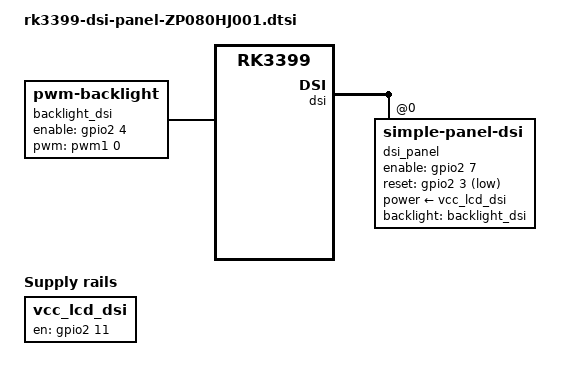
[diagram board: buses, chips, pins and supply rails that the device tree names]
/*
 * Copyright (c) 2016 Fuzhou Rockchip Electronics Co., Ltd
 *
 * This file is dual-licensed: you can use it either under the terms
 * of the GPL or the X11 license, at your option. Note that this dual
 * licensing only applies to this file, and not this project as a
 * whole.
 *
 *  a) This file is free software; you can redistribute it and/or
 *     modify it under the terms of the GNU General Public License as
 *     published by the Free Software Foundation; either version 2 of the
 *     License, or (at your option) any later version.
 *
 *     This file is distributed in the hope that it will be useful,
 *     but WITHOUT ANY WARRANTY; without even the implied warranty of
 *     MERCHANTABILITY or FITNESS FOR A PARTICULAR PURPOSE.  See the
 *     GNU General Public License for more details.
 *
 * Or, alternatively,
 *
 *  b) Permission is hereby granted, free of charge, to any person
 *     obtaining a copy of this software and associated documentation
 *     files (the "Software"), to deal in the Software without
 *     restriction, including without limitation the rights to use,
 *     copy, modify, merge, publish, distribute, sublicense, and/or
 *     sell copies of the Software, and to permit persons to whom the
 *     Software is furnished to do so, subject to the following
 *     conditions:
 *
 *     The above copyright notice and this permission notice shall be
 *     included in all copies or substantial portions of the Software.
 *
 *     THE SOFTWARE IS PROVIDED "AS IS", WITHOUT WARRANTY OF ANY KIND,
 *     EXPRESS OR IMPLIED, INCLUDING BUT NOT LIMITED TO THE WARRANTIES
 *     OF MERCHANTABILITY, FITNESS FOR A PARTICULAR PURPOSE AND
 *     NONINFRINGEMENT. IN NO EVENT SHALL THE AUTHORS OR COPYRIGHT
 *     HOLDERS BE LIABLE FOR ANY CLAIM, DAMAGES OR OTHER LIABILITY,
 *     WHETHER IN AN ACTION OF CONTRACT, TORT OR OTHERWISE, ARISING
 *     FROM, OUT OF OR IN CONNECTION WITH THE SOFTWARE OR THE USE OR
 *     OTHER DEALINGS IN THE SOFTWARE.
 */

/ {
	vcc_lcd_dsi: vcc-lcd-dsi-regulator {
		compatible = "regulator-fixed";
		status = "okay";
		regulator-always-on;
		regulator-boot-on;
		enable-active-high;
		gpio = <&gpio2 11 GPIO_ACTIVE_HIGH>;
		regulator-name = "vcc_lcd_dsi";
	};

	backlight_dsi: backlight-dsi {
		status = "okay";
		compatible = "pwm-backlight";
		pwms = <&pwm1 0 25000 0>;
		brightness-levels = <
			  0   0   1   1   2   2   3   3
			  4   4   5   5   6   6   7   7
			  8   8   9   9  10  10  11  11
			 12  12  13  13  14  14  15  15
			 16  16  17  17  18  18  19  19
			 20  20  21  21  22  22  23  23
			 24  24  25  25  26  26  27  27
			 28  28  29  29  30  30  31  31
			 32  32  33  33  34  34  35  35
			 36  36  37  37  38  38  39  39
			 40  40  41  41  42  42  43  43
			 44  44  45  45  46  46  47  47
			 48  48  49  49  50  50  51  51
			 52  52  53  53  54  54  55  55
			 56  56  57  57  58  58  59  59
			 60  60  61  61  62  62  63  63
			 64  64  65  65  66  66  67  67
			 68  68  69  69  70  70  71  71
			 72  72  73  73  74  74  75  75
			 76  76  77  77  78  78  79  79
			 80  80  81  81  81  82  83  83
			 84  84  85  85  86  86  87  87
			 88  88  89  89  90  90  91  91
			 92  92  93  93  94  94  95  95
			 96  96  97  97  98  98  99  99
			 100 100 101 101 102 102 103 103
			 104 104 105 105 106 106 107 107
			 108 108 109 109 110 110 110 110
			 111 111 112 112 113 113 114 114
			 115 115 116 116 117 117 118 118
			 119 119 120 120 121 121 122 122
			 123 123 124 124 125 125 126>;
		default-brightness-level = <60>;
		enable-gpios = <&gpio2 4 GPIO_ACTIVE_HIGH>;
	};
};

&dsi {
	status = "okay";
//	rockchip,lane-rate = <1000>;

	dsi_panel: panel@0 {
		compatible ="simple-panel-dsi";
		status = "okay";
		reg = <0>;
		reset-delay-ms = <1>;
		init-delay-ms = <20>;
		enable-delay-ms = <120>;
		prepare-delay-ms = <2>;
		disable-delay-ms = <50>;
		unprepare-delay-ms = <20>;
		backlight = <&backlight_dsi>;
		power-supply = <&vcc_lcd_dsi>;
		enable-gpios = <&gpio2 7 GPIO_ACTIVE_HIGH>;
		reset-gpios = <&gpio2 3 GPIO_ACTIVE_LOW>;
		dsi,format = <MIPI_DSI_FMT_RGB888>;
		dsi,flags = <(MIPI_DSI_MODE_VIDEO | MIPI_DSI_MODE_VIDEO_BURST)>;
		dsi,lanes = <4>;

#if 0
		panel-init-sequence = [
			 15 00 02 E0 00
			 15 00 02 E1 93
			 15 00 02 E2 65
			 15 00 02 E3 F8
			 15 00 02 80 03
			 15 00 02 E0 01
			 15 00 02 00 00
			 15 00 02 01 6F
			 15 00 02 03 00
			 15 00 02 04 6A
			 15 00 02 17 00
			 15 00 02 18 AF
			 15 00 02 19 01
			 15 00 02 1A 00
			 15 00 02 1B AF
			 15 00 02 1C 01
			 15 00 02 1F 3E
			 15 00 02 20 28
			 15 00 02 21 28
			 15 00 02 22 7E
			 15 00 02 35 26
			 15 00 02 37 09
			 15 00 02 38 04
			 15 00 02 39 00
			 15 00 02 3A 01
			 15 00 02 3C 7C
			 15 00 02 3D FF
			 15 00 02 3E FF
			 15 00 02 3F 7F
			 15 00 02 40 06
			 15 00 02 41 A0
			 15 00 02 42 81
			 15 00 02 43 08
			 15 00 02 44 0B
			 15 00 02 45 28
			 15 00 02 55 01
			 15 00 02 57 69
			 15 00 02 59 0A
			 15 00 02 5A 28
			 15 00 02 5B 14
			 15 00 02 5D 7C
			 15 00 02 5E 65
			 15 00 02 5F 55
			 15 00 02 60 47
			 15 00 02 61 43
			 15 00 02 62 32
			 15 00 02 63 34
			 15 00 02 64 1C
			 15 00 02 65 33
			 15 00 02 66 31
			 15 00 02 67 30
			 15 00 02 68 4E
			 15 00 02 69 3C
			 15 00 02 6A 44
			 15 00 02 6B 35
			 15 00 02 6C 31
			 15 00 02 6D 23
			 15 00 02 6E 11
			 15 00 02 6F 00
			 15 00 02 70 7C
			 15 00 02 71 65
			 15 00 02 72 55
			 15 00 02 73 47
			 15 00 02 74 43
			 15 00 02 75 32
			 15 00 02 76 34
			 15 00 02 77 1C
			 15 00 02 78 33
			 15 00 02 79 31
			 15 00 02 7A 30
			 15 00 02 7B 4E
			 15 00 02 7C 3C
			 15 00 02 7D 44
			 15 00 02 7E 35
			 15 00 02 7F 31
			 15 00 02 80 23
			 15 00 02 81 11
			 15 00 02 82 00
			 15 00 02 E0 02
			 15 00 02 00 1E
			 15 00 02 01 1E
			 15 00 02 02 41
			 15 00 02 03 41
			 15 00 02 04 1F
			 15 00 02 05 1F
			 15 00 02 06 1F
			 15 00 02 07 1F
			 15 00 02 08 1F
			 15 00 02 09 1F
			 15 00 02 0A 1E
			 15 00 02 0B 1E
			 15 00 02 0C 1F
			 15 00 02 0D 47
			 15 00 02 0E 47
			 15 00 02 0F 45
			 15 00 02 00 45
			 15 00 02 11 4B
			 15 00 02 12 4B
			 15 00 02 13 49
			 15 00 02 14 49
			 15 00 02 15 1F
			 15 00 02 16 1E
			 15 00 02 17 1E
			 15 00 02 18 40
			 15 00 02 19 40
			 15 00 02 1A 1F
			 15 00 02 1B 1F
			 15 00 02 1C 1F
			 15 00 02 1D 1F
			 15 00 02 1E 1F
			 15 00 02 1F 1F
			 15 00 02 20 1E
			 15 00 02 21 1E
			 15 00 02 22 1F
			 15 00 02 23 46
			 15 00 02 24 46
			 15 00 02 25 44
			 15 00 02 26 44
			 15 00 02 27 4A
			 15 00 02 28 4A
			 15 00 02 29 48
			 15 00 02 2A 48
			 15 00 02 2B 1F
			 15 00 02 2C 1F
			 15 00 02 2D 1F
			 15 00 02 2E 40
			 15 00 02 2F 40
			 15 00 02 30 1F
			 15 00 02 31 1F
			 15 00 02 32 1E
			 15 00 02 33 1E
			 15 00 02 34 1F
			 15 00 02 35 1F
			 15 00 02 36 1E
			 15 00 02 37 1E
			 15 00 02 38 1F
			 15 00 02 39 48
			 15 00 02 3A 48
			 15 00 02 3B 4A
			 15 00 02 3C 4A
			 15 00 02 3D 44
			 15 00 02 3E 44
			 15 00 02 3F 46
			 15 00 02 40 46
			 15 00 02 41 1F
			 15 00 02 42 1F
			 15 00 02 43 1F
			 15 00 02 44 41
			 15 00 02 45 41
			 15 00 02 46 1F
			 15 00 02 47 1F
			 15 00 02 48 1E
			 15 00 02 49 1E
			 15 00 02 4A 1E
			 15 00 02 4B 1F
			 15 00 02 4C 1E
			 15 00 02 4D 1E
			 15 00 02 4E 1F
			 15 00 02 4F 49
			 15 00 02 50 49
			 15 00 02 51 4B
			 15 00 02 52 4B
			 15 00 02 53 45
			 15 00 02 54 45
			 15 00 02 55 47
			 15 00 02 56 47
			 15 00 02 57 1F
			 15 00 02 58 40
			 15 00 02 5B 30
			 15 00 02 5C 03
			 15 00 02 5D 30
			 15 00 02 5E 01
			 15 00 02 5F 02
			 15 00 02 63 14
			 15 00 02 64 6A
			 15 00 02 67 73
			 15 00 02 68 05
			 15 00 02 69 14
			 15 00 02 6A 6A
			 15 00 02 6B 08
			 15 00 02 6C 00
			 15 00 02 6D 00
			 15 00 02 6E 00
			 15 00 02 6F 88
			 15 00 02 77 DD
			 15 00 02 79 0E
			 15 00 02 7A 03
			 15 00 02 7D 14
			 15 00 02 7E 6A
			 15 00 02 E0 04
			 15 00 02 09 11
			 15 00 02 0E 48
			 15 00 02 2B 2B
			 15 00 02 2D 03
			 15 00 02 2E 44
			 15 00 02 E0 00
			 15 00 02 E6 02
			 15 00 02 E7 0C
			 05 78 01 11
			 05 05 01 29
		];
#else
		panel-init-sequence = [
			15 00 02 E0 00
			 15 00 02 E1 93
			 15 00 02 E2 65
			 15 00 02 E3 F8
			 15 00 02 80 03
			 15 00 02 E0 04
			 15 00 02 2D 03
			 15 00 02 E0 01
			 15 00 02 01 A0
			 15 00 02 17 00
			 15 00 02 18 B1
			 15 00 02 19 01
			 15 00 02 1A 00
			 15 00 02 1B B1
			 15 00 02 1C 01
			 15 00 02 1F 3E
			 15 00 02 20 2D
			 15 00 02 21 2D
			 15 00 02 22 0E
			 15 00 02 37 19
			 15 00 02 38 05
			 15 00 02 39 08
			 15 00 02 3A 12
			 15 00 02 3C 78
			 15 00 02 3E 80
			 15 00 02 3F 80
			 15 00 02 40 06
			 15 00 02 41 A0
			 15 00 02 55 01
			 15 00 02 56 01
			 15 00 02 57 69
			 15 00 02 58 0A
			 15 00 02 59 0A
			 15 00 02 5A 28
			 15 00 02 5B 19
			 15 00 02 5D 7C
			 15 00 02 5E 60
			 15 00 02 5F 50
			 15 00 02 60 43
			 15 00 02 61 3F
			 15 00 02 62 30
			 15 00 02 63 34
			 15 00 02 64 1E
			 15 00 02 65 37
			 15 00 02 66 35
			 15 00 02 67 34
			 15 00 02 68 52
			 15 00 02 69 3F
			 15 00 02 6A 44
			 15 00 02 6B 35
			 15 00 02 6C 2F
			 15 00 02 6D 21
			 15 00 02 6E 10
			 15 00 02 6F 00
			 15 00 02 70 7C
			 15 00 02 71 60
			 15 00 02 72 50
			 15 00 02 73 43
			 15 00 02 74 3F
			 15 00 02 75 30
			 15 00 02 76 34
			 15 00 02 77 1E
			 15 00 02 78 37
			 15 00 02 79 35
			 15 00 02 7A 34
			 15 00 02 7B 52
			 15 00 02 7C 3F
			 15 00 02 7D 44
			 15 00 02 7E 35
			 15 00 02 7F 2F
			 15 00 02 80 21
			 15 00 02 81 10
			 15 00 02 82 00
			 15 00 02 E0 02
			 15 00 02 00 47
			 15 00 02 01 47
			 15 00 02 02 45
			 15 00 02 03 45
			 15 00 02 04 4B
			 15 00 02 05 4B
			 15 00 02 06 49
			 15 00 02 07 49
			 15 00 02 08 41
			 15 00 02 09 1F
			 15 00 02 0A 1F
			 15 00 02 0B 1F
			 15 00 02 0C 1F
			 15 00 02 0D 1F
			 15 00 02 0E 1F
			 15 00 02 0F 43
			 15 00 02 10 1F
			 15 00 02 11 1F
			 15 00 02 12 1F
			 15 00 02 13 1F
			 15 00 02 14 1F
			 15 00 02 15 1F
			 15 00 02 16 46
			 15 00 02 17 46
			 15 00 02 18 44
			 15 00 02 19 44
			 15 00 02 1A 4A
			 15 00 02 1B 4A
			 15 00 02 1C 48
			 15 00 02 1D 48
			 15 00 02 1E 40
			 15 00 02 1F 1F
			 15 00 02 20 1F
			 15 00 02 21 1F
			 15 00 02 22 1F
			 15 00 02 23 1F
			 15 00 02 24 1F
			 15 00 02 25 42
			 15 00 02 26 1F
			 15 00 02 27 1F
			 15 00 02 28 1F
			 15 00 02 29 1F
			 15 00 02 2A 1F
			 15 00 02 2B 1F
			 15 00 02 58 40
			 15 00 02 5B 30
			 15 00 02 5C 03
			 15 00 02 5D 30
			 15 00 02 5E 01
			 15 00 02 5F 02
			 15 00 02 63 03
			 15 00 02 64 6B
			 15 00 02 67 73
			 15 00 02 68 05
			 15 00 02 69 06
			 15 00 02 6A 6B
			 15 00 02 6B 08
			 15 00 02 6C 00
			 15 00 02 6D 04
			 15 00 02 6E 04
			 15 00 02 6F 88
			 15 00 02 E0 01
			 15 00 02 0E 01
			 15 00 02 E0 03
			 15 00 02 98 2F
			 15 00 02 E0 04
			 15 00 02 2B 2B
			 15 00 02 2E 44
			 15 00 02 E0 00
			 15 00 02 E6 02
			 15 00 02 E7 02
			 05 A0 01 11
			 05 05 01 29
		];
#endif
		panel-exit-sequence = [
			 05 05 01 28
			 05 78 01 10
		];

		display-timings {
			native-mode = <&timing0>;

			timing0: timing0 {
				clock-frequency = <68000000>;
				hactive = <800>;
				vactive = <1280>;
				hback-porch = <20>;
				hfront-porch = <32>;
				vback-porch = <4>;
				vfront-porch = <8>;
				hsync-len = <20>;
				vsync-len = <4>;
				hsync-active = <0>;
				vsync-active = <0>;
				de-active = <0>;
				pixelclk-active = <0>;
			};
		};
	};
};
